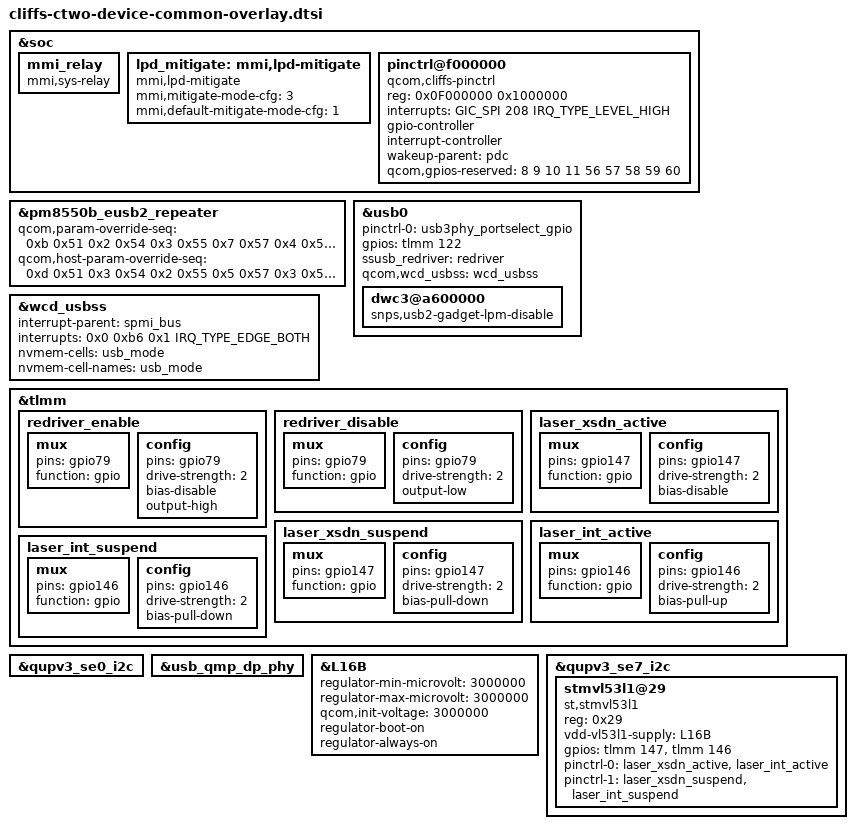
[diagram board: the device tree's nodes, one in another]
/* Copyright (c) 2021, The Linux Foundation. All rights reserved.
 *
 * This program is free software; you can redistribute it and/or modify
 * it under the terms of the GNU General Public License version 2 and
 * only version 2 as published by the Free Software Foundation.
 *
 * This program is distributed in the hope that it will be useful,
 * but WITHOUT ANY WARRANTY; without even the implied warranty of
 * MERCHANTABILITY or FITNESS FOR A PARTICULAR PURPOSE.  See the
 * GNU General Public License for more details.
 */

/* This file is only for ctwo device */

#include <dt-bindings/interrupt-controller/arm-gic.h>
#include "cliffs-ctwo-products-common-overlay.dtsi"
#include "cliffs-ctwo-haptics-overlay.dtsi"
#include "cliffs-ctwo-fingerprint-overlay.dtsi"
#include "cliffs-ctwo-charger-overlay.dtsi"
#include "cliffs-moto-common-st-nfc.dtsi"
#include "cliffs-ctwo-touchscreen-overlay.dtsi"
#include "moto-ctwo-wl2868c.dtsi"
#include "cliffs-moto-wcn7851-s3e-overlay.dtsi"

#include "cliffs-ctwo-thermal-overlay.dtsi"
#include "cliffs-ctwo-evb-sensor-overlay.dtsi"
&soc {
	mmi_relay {
		compatible = "mmi,sys-relay";
	};

	lpd_mitigate: mmi,lpd-mitigate {
		compatible = "mmi,lpd-mitigate";
		mmi,mitigate-mode-cfg = <3>;
		mmi,default-mitigate-mode-cfg = <1>;
	};

	pinctrl@f000000 {
		compatible = "qcom,cliffs-pinctrl";
		reg = <0x0F000000 0x1000000>;
		interrupts = <GIC_SPI 208 IRQ_TYPE_LEVEL_HIGH>;
		gpio-controller;
		#gpio-cells = <2>;
		interrupt-controller;
		#interrupt-cells = <2>;
		wakeup-parent = <&pdc>;
		qcom,gpios-reserved = <8 9 10 11 56 57 58 59 60>;
	};
};

&pm8550b_eusb2_repeater {
	qcom,param-override-seq =
		/* <value reg_offset> */
		/* Adjust HS trasmit amplitude */
		<0xb 0x51
		/* Squelch detection threshold */
		 0x2 0x54
		/* USB2 Tx slew rate */
		 0x3 0x55
		/* Tx pre-emphasis tuning */
		 0x7 0x57
		/* HS disconnect threshold */
		 0x4 0x53
		/* slew rate */
		 0x00 0x59>;
	qcom,host-param-override-seq =
		/* <value reg_offset> */
		/* Adjust HS trasmit amplitude */
		<0xd 0x51
		/* Squelch detection threshold */
		 0x3 0x54
		/*USB2 Tx slew rate */
		 0x2 0x55
		/* Tx pre-emphasis tuning */
		 0x5 0x57
		/* HS disconnect threshold */
		 0x3 0x53
		/* slew rate */
		 0x00 0x59>;
};

&usb0 {
	dwc3@a600000 {
		snps,usb2-gadget-lpm-disable;
	};
};

&wcd_usbss {
	interrupt-parent = <&spmi_bus>;
	interrupts = <0x0 0xb6 0x1 IRQ_TYPE_EDGE_BOTH>;
	interrupt-names = "usb_wcd";
	nvmem-cells = <&usb_mode>;
	nvmem-cell-names = "usb_mode";
};

&tlmm {
	redriver_enable: redriver_enable {
		mux {
			pins = "gpio79";
			function = "gpio";
		};

		config {
			pins = "gpio79";
			drive-strength = <2>;
			bias-disable; /* NO PULL */
			output-high;
		};
	};
	redriver_disable: redriver_disable {
		mux {
			pins = "gpio79";
			function = "gpio";
		};

		config {
			pins = "gpio79";
			drive-strength = <2>;
			output-low;
		};
	};
};

&qupv3_se0_i2c {
	status = "ok";
	#include "cliffs-moto-common-redriver.dtsi"
};

&usb_qmp_dp_phy {
	pinctrl-names = "unused";
};

&usb0 {
	pinctrl-names = "default";
	pinctrl-0 = <&usb3phy_portselect_gpio>;
	gpios = <&tlmm 122 0>;
	ssusb_redriver = <&redriver>;
	qcom,wcd_usbss = <&wcd_usbss>;
};

&L16B {
	regulator-min-microvolt = <3000000>;
	regulator-max-microvolt = <3000000>;
	qcom,init-voltage = <3000000>;
	regulator-boot-on;
	regulator-always-on;
};

&tlmm {
        laser_xsdn_active: laser_xsdn_active {
		mux {
			pins = "gpio147";
			function = "gpio";
		};

		config {
			pins = "gpio147";
			drive-strength = <2>;
			bias-disable;
		};
	};

	laser_xsdn_suspend: laser_xsdn_suspend {
		mux {
			pins = "gpio147";
			function = "gpio";
		};

		config {
			pins = "gpio147";
			drive-strength = <2>;
			bias-pull-down; /* PULL DOWN */
		};
	};

	laser_int_active: laser_int_active {
		mux {
			pins = "gpio146";
			function = "gpio";
		};

		config {
			pins = "gpio146";
			drive-strength = <2>;
			bias-pull-up; /* PULL UP */
		};
	};

	laser_int_suspend: laser_int_suspend {
		mux {
			pins = "gpio146";
			function = "gpio";
		};

		config {
			pins = "gpio146";
			drive-strength = <2>;
			bias-pull-down; /* PULL DOWN */
		};
	};
};

&qupv3_se7_i2c {
	status = "okay";
	stmvl53l1@29 {
		status = "ok";
		compatible = "st,stmvl53l1";
		reg = <0x29>;
		vdd-vl53l1-supply = <&L16B>;
		gpios = <&tlmm 147 0>, <&tlmm 146 0>;
		pinctrl-names = "laser_default", "laser_suspend";
		pinctrl-0 = <&laser_xsdn_active &laser_int_active>;
		pinctrl-1 = <&laser_xsdn_suspend &laser_int_suspend>;
	};
};
